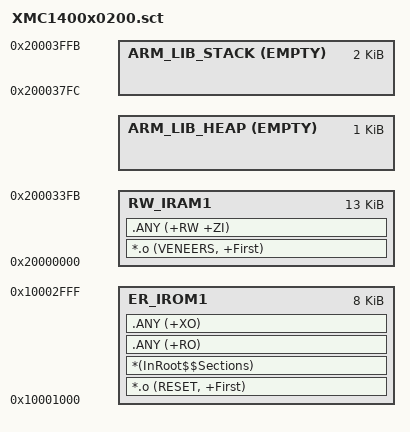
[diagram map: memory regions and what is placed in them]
#! armcc -E
; command above MUST be in first line (no comment above!)

;*********************************************************************************************************************
;* @file     XMC1400x0200.sct
;* @brief    Scatter-Loading Description File for Infineon XMC1400 200K Flash Devices
;* @version  V1.2
;* @date     09 Jan 2021
;*
;* @cond
;*********************************************************************************************************************
;* Copyright (c) 2018-2020, Infineon Technologies AG
;* All rights reserved.                        
;*                                             
;* Boost Software License - Version 1.0 - August 17th, 2003
;* 
;* Permission is hereby granted, free of charge, to any person or organization
;* obtaining a copy of the software and accompanying documentation covered by
;* this license (the "Software") to use, reproduce, display, distribute,
;* execute, and transmit the Software, and to prepare derivative works of the
;* Software, and to permit third-parties to whom the Software is furnished to
;* do so, all subject to the following:
;* 
;* The copyright notices in the Software and this entire statement, including
;* the above license grant, this restriction and the following disclaimer,
;* must be included in all copies of the Software, in whole or in part, and
;* all derivative works of the Software, unless such copies or derivative
;* works are solely in the form of machine-executable object code generated by
;* a source language processor.
;* 
;* THE SOFTWARE IS PROVIDED "AS IS", WITHOUT WARRANTY OF ANY KIND, EXPRESS OR
;* IMPLIED, INCLUDING BUT NOT LIMITED TO THE WARRANTIES OF MERCHANTABILITY,
;* FITNESS FOR A PARTICULAR PURPOSE, TITLE AND NON-INFRINGEMENT. IN NO EVENT
;* SHALL THE COPYRIGHT HOLDERS OR ANYONE DISTRIBUTING THE SOFTWARE BE LIABLE
;* FOR ANY DAMAGES OR OTHER LIABILITY, WHETHER IN CONTRACT, TORT OR OTHERWISE,
;* ARISING FROM, OUT OF OR IN CONNECTION WITH THE SOFTWARE OR THE USE OR OTHER
;* DEALINGS IN THE SOFTWARE.
;*                                                                              
;* To improve the quality of the software, users are encouraged to share 
;* modifications, enhancements or bug fixes with Infineon Technologies AG 
;* at XMCSupport@infineon.com.
;*********************************************************************************************************************
;*
;**************************** Change history ********************************
;* V1.1, Nov, 09, 2018 JFT:Initial version
;* V1.2, Jan, 09, 2021 JFT:Added heap and stack areas
;*
;* @endcond 
;*

/*
;-------- <<< Use Configuration Wizard in Context Menu >>> -------------------
*/

/*--------------------- Stack / Heap Configuration ---------------------------
; <h> Stack / Heap Configuration
;   <o0> Stack Size (in Bytes) <0x0-0xFFFFFFFF:8>
;   <o1> Heap Size (in Bytes) <0x0-0xFFFFFFFF:8>
; </h>
 *----------------------------------------------------------------------------*/
#define __STACK_SIZE       0x00000800
#define __HEAP_SIZE        0x00000400

/*
;------------- <<< end of configuration section >>> ---------------------------
*/

#define __ROM_BASE     0x10001000
#define __ROM_SIZE     0x00002000

#define __RAM_BASE     0x20000000
#define __RAM_SIZE     0x00004000

#define __NO_INIT_SIZE 4

/*----------------------------------------------------------------------------
  User Stack & Heap boundary definition
 *----------------------------------------------------------------------------*/
#define __STACK_TOP    (__RAM_BASE + __RAM_SIZE - __NO_INIT_SIZE)    /* starts at end of RAM */
#define __HEAP_BASE    (AlignExpr(+0, 8))           /* starts after RW_RAM section, 8 byte aligned */

/*----------------------------------------------------------------------------
  Scatter File Definitions definition
 *----------------------------------------------------------------------------*/
#define __RW_BASE       __RAM_BASE
#define __RW_SIZE      (__RAM_SIZE - __STACK_SIZE - __HEAP_SIZE - __NO_INIT_SIZE)


LR_IROM1 __ROM_BASE __ROM_SIZE  {    ; load region size_region
  ER_IROM1 __ROM_BASE __ROM_SIZE  {  ; load address = execution address
   *.o (RESET, +First)
   *(InRoot$$Sections)
   .ANY (+RO)
   .ANY (+XO)
  }

  RW_IRAM1 __RW_BASE __RW_SIZE  {  ; RW data
   *.o (VENEERS, +First)
   .ANY (+RW +ZI)
  }

#if __HEAP_SIZE > 0
  ARM_LIB_HEAP  __HEAP_BASE EMPTY  __HEAP_SIZE  {   ; Reserve empty region for heap
  }
#endif

  ARM_LIB_STACK __STACK_TOP EMPTY -__STACK_SIZE {   ; Reserve empty region for stack
  }

}

